AUTOSAR XML (schema 4-0-3)
package /ComponentTypes
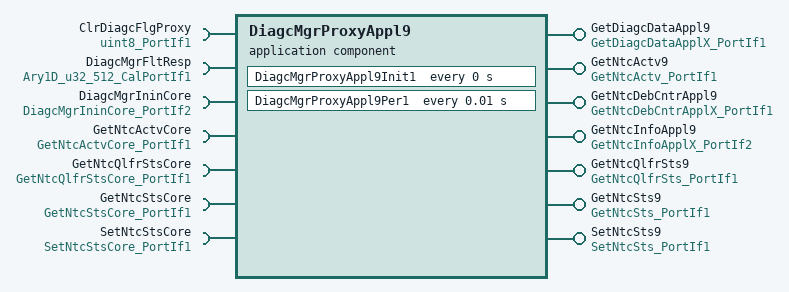
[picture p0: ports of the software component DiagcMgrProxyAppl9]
  application sw component type DiagcMgrProxyAppl9
    7 x provide port, all with server-com-spec{operation=Oper, queue-length=1}:
      GetDiagcDataAppl9: provided-interface=GetDiagcDataApplX_PortIf1
      GetNtcActv9: provided-interface=GetNtcActv_PortIf1
      GetNtcDebCntrAppl9: provided-interface=GetNtcDebCntrApplX_PortIf1
      GetNtcInfoAppl9: provided-interface=GetNtcInfoApplX_PortIf2
      GetNtcQlfrSts9: provided-interface=GetNtcQlfrSts_PortIf1
      GetNtcSts9: provided-interface=GetNtcSts_PortIf1
      SetNtcSts9: provided-interface=SetNtcSts_PortIf1
    7 x require port:
      ClrDiagcFlgProxy: nonqueued-receiver-com-spec{data-element=Val, filter=data-filter-type=ALWAYS, init-value=0}, required-interface=uint8_PortIf1
      DiagcMgrFltResp: parameter-require-com-spec{init-value=[0, 2147487488, 2147487488, 2147487488, 2147487488, 2147487488, 2147487488, 2147487488, 2147487488, 2147487488, 2147487488, 2147487488, 2147487488, 2147487488, 2147487488, 2147487488, 2147487488, 2147487488, 2147487488, 2147487488, 2147487488, 2147487488, 2147487488, 2147487488, 2147487488, 2147487488, 2147487488, 2147487488, 2147487488, 2147487488, 2147487488, 2147487488, 2147487488, 2147487488, 2147487488, 2147487488, 2147487488, 2147487488, 2147487488, 2147487488, 2147487488, 2147487488, 2147487488, 2147487488, 2147487488, 2147487488, 2147487488, 2147487488, 2147487488, 2147487488, 2147487488, 2147487488, 2147487488, 2147487488, 2147487488, 2147487488, 2147487488, 2147487488, 2147487488, 2147487488, 2147487488, 2147487488, 2147487488, 2147487488, 2147487488, 2147487488, 2147487488, 2147487488, 2147487488, 2147487488, 2147487488, 2147487488, 2147487488, 2147487488, 2147487488, 2147487488, 2147487488, 2147487488, 2147487488, 2147487488, 2147487488, 2147487488, 2147487488, 2147487488, 2147487488, 2147487488, 2147487488, 2147487488, 2147487488, 2147487488, 2147487488, 2147487488, 2147487488, 2147487488, 2147487488, 2147487488, 2147487488, 2147487488, 2147487488, 2147487488, 2147487488, 2147487488, 2147487488, 2147487488, 2147487488, 2147487488, 2147487488, 2147487488, 2147487488, 2147487488, 2147487488, 2147487488, 2147487488, 2147487488, 2147487488, 2147487488, 2147487488, 2147487488, 2147487488, 2147487488, 2147487488, 2147487488, 2147487488, 2147487488, 2147487488, 2147487488, 2147487488, 2147487488, 2147487488, 2147487488, 2147487488, 2147487488, 2147487488, 2147487488, 2147487488, 2147487488, 2147487488, 2147487488, 2147487488, 2147487488, 2147487488, 2147487488, 2147487488, 2147487488, 2147487488, 2147487488, 2147487488, 2147487488, 2147487488, 2147487488, 2147487488, 2147487488, 2147487488, 2147487488, 2147487488, 2147487488, 2147487488, 2147487488, 2147487488, 2147487488, 2147487488, 2147487488, 2147487488, 2147487488, 2147487488, 2147487488, 2147487488, 2147487488, 2147487488, 2147487488, 2147487488, 2147487488, 2147487488, 2147487488, 2147487488, 2147487488, 2147487488, 2147487488, 2147487488, 2147487488, 2147487488, 2147487488, 2147487488, 2147487488, 2147487488, 2147487488, 2147487488, 2147487488, 2147487488, 2147487488, 2147487488, 2147487488, 2147487488, 2147487488, 2147487488, 2147487488, 2147487488, 2147487488, 2147487488, 2147487488, 2147487488, 2147487488, 2147487488, 2147487488, 2147487488, 2147487488, 2147487488, 2147487488, 2147487488, 2147487488, 2147487488, 2147487488, 2147487488, 2147487488, 2147487488, 2147487488, 2147487488, 2147487488, 2147487488, 2147487488, 2147487488, 2147487488, 2147487488, 2147487488, 2147487488, 2147487488, 2147487488, 2147487488, 2147487488, 2147487488, 2147487488, 2147487488, 2147487488, 2147487488, 2147487488, 2147487488, 2147487488, 2147487488, 2147487488, 2147487488, 2147487488, 2147487488, 2147487488, 2147487488, 2147487488, 2147487488, 2147487488, 2147487488, 2147487488, 2147487488, 2147487488, 2147487488, 2147487488, 2147487488, 2147487488, 2147487488, 2147487488, 2147487488, 2147487488, 2147487488, 2147487488, 2147487488, 2147487488, 2147487488, 2147487488, 2147487488, 2147487488, 2147487488, 2147487488, 2147487488, 2147487488, 2147487488, 2147487488, 2147487488, 2147487488, 2147487488, 2147487488, 2147487488, 2147487488, 2147487488, 2147487488, 2147487488, 2147487488, 2147487488, 2147487488, 2147487488, 2147487488, 2147487488, 2147487488, 2147487488, 2147487488, 2147487488, 2147487488, 2147487488, 2147487488, 2147487488, 2147487488, 2147487488, 2147487488, 2147487488, 2147487488, 2147487488, 2147487488, 2147487488, 2147487488, 2147487488, 2147487488, 2147487488, 2147487488, 2147487488, 2147487488, 2147487488, 2147487488, 2147487488, 2147487488, 2147487488, 2147487488, 2147487488, 2147487488, 2147487488, 2147487488, 2147487488, 2147487488, 2147487488, 2147487488, 2147487488, 2147487488, 2147487488, 2147487488, 2147487488, 2147487488, 2147487488, 2147487488, 2147487488, 2147487488, 2147487488, 2147487488, 2147487488, 2147487488, 2147487488, 2147487488, 2147487488, 2147487488, 2147487488, 2147487488, 2147487488, 2147487488, 2147487488, 2147487488, 2147487488, 2147487488, 2147487488, 2147487488, 2147487488, 2147487488, 2147487488, 2147487488, 2147487488, 2147487488, 2147487488, 2147487488, 2147487488, 2147487488, 2147487488, 2147487488, 2147487488, 2147487488, 2147487488, 2147487488, 2147487488, 2147487488, 2147487488, 2147487488, 2147487488, 2147487488, 2147487488, 2147487488, 2147487488, 2147487488, 2147487488, 2147487488, 2147487488, 2147487488, 2147487488, 2147487488, 2147487488, 2147487488, 2147487488, 2147487488, 2147487488, 2147487488, 2147487488, 2147487488, 2147487488, 2147487488, 2147487488, 2147487488, 2147487488, 2147487488, 2147487488, 2147487488, 2147487488, 2147487488, 2147487488, 2147487488, 2147487488, 2147487488, 2147487488, 2147487488, 2147487488, 2147487488, 2147487488, 2147487488, 2147487488, 2147487488, 2147487488, 2147487488, 2147487488, 2147487488, 2147487488, 2147487488, 2147487488, 2147487488, 2147487488, 2147487488, 2147487488, 2147487488, 2147487488, 2147487488, 2147487488, 2147487488, 2147487488, 2147487488, 2147487488, 2147487488, 2147487488, 2147487488, 2147487488, 2147487488, 2147487488, 2147487488, 2147487488, 2147487488, 2147487488, 2147487488, 2147487488, 2147487488, 2147487488, 2147487488, 2147487488, 2147487488, 2147487488, 2147487488, 2147487488, 2147487488, 2147487488, 2147487488, 2147487488, 2147487488, 2147487488, 2147487488, 2147487488, 2147487488, 2147487488, 2147487488, 2147487488, 2147487488, 2147487488, 2147487488, 2147487488, 2147487488, 2147487488, 2147487488, 2147487488, 2147487488, 2147487488, 2147487488, 2147487488, 2147487488, 2147487488, 2147487488, 2147487488, 2147487488, 2147487488, 2147487488, 2147487488, 2147487488, 2147487488, 2147487488, 2147487488, 2147487488, 2147487488, 2147487488, 2147487488, 2147487488, 2147487488, 2147487488, 2147487488, 2147487488, 2147487488, 2147487488, 2147487488, 2147487488, 2147487488, 2147487488, 2147487488, 2147487488, 2147487488, 2147487488, 2147487488, 2147487488, 2147487488], parameter=Ary1D}, required-interface=Ary1D_u32_512_CalPortIf1
      DiagcMgrIninCore: required-interface=DiagcMgrIninCore_PortIf2
      GetNtcActvCore: required-interface=GetNtcActvCore_PortIf1
      GetNtcQlfrStsCore: required-interface=GetNtcQlfrStsCore_PortIf1
      GetNtcStsCore: required-interface=GetNtcStsCore_PortIf1
      SetNtcStsCore: required-interface=SetNtcStsCore_PortIf1
    behavior DiagcMgrProxyAppl9_InternalBehavior
      exclusive area DiagcMgrProxyAppl9
      ar-typed-per-instance-memorys:
        5 x data:
          DiagcData9: sw-calibration-access=READ-ONLY, type=DiagcDataRec1
          DiagcMgrNtcInfo9Ary: type=Ary1D_NtcInfoRec4_DiagcMgrProxyAppl9
          DiagcMgrNtcInfo9DebCntrAry: type=Ary1D_s16_DiagcMgrProxyAppl9
          PrevClrNtcFlg9: sw-calibration-access=READ-ONLY, type=uint8
          ProxySetNtcData9: sw-calibration-access=READ-ONLY, type=DiagcDataRec1
      timing event DiagcMgrProxyAppl9_InitEvent: start-on-event=DiagcMgrProxyAppl9Init1, period=0
      timing event TMT_DiagcMgrProxyAppl9Per1: start-on-event=DiagcMgrProxyAppl9Per1, period=0.01
      7 x operation invoked event:
        OIT_GetDiagcDataAppl9_Oper_GetDiagcDataAppl9_Oper: start-on-event=GetDiagcDataAppl9_Oper, operation=GetDiagcDataAppl9.Oper
        OIT_GetNtcActv9_Oper_GetNtcActv9_Oper: start-on-event=GetNtcActv9_Oper, operation=GetNtcActv9.Oper
        OIT_GetNtcDebCntrAppl9_Oper_GetNtcDebCntrAppl9_Oper: start-on-event=GetNtcDebCntrAppl9_Oper, operation=GetNtcDebCntrAppl9.Oper
        OIT_GetNtcInfoAppl9_Oper_GetNtcInfoAppl9_Oper: start-on-event=GetNtcInfoAppl9_Oper, operation=GetNtcInfoAppl9.Oper
        OIT_GetNtcQlfrSts9_Oper_GetNtcQlfrSts9_Oper: start-on-event=GetNtcQlfrSts9_Oper, operation=GetNtcQlfrSts9.Oper
        OIT_GetNtcSts9_Oper_GetNtcSts9_Oper: start-on-event=GetNtcSts9_Oper, operation=GetNtcSts9.Oper
        OIT_SetNtcSts9_Oper_SetNtcSts9_Oper: start-on-event=SetNtcSts9_Oper, operation=SetNtcSts9.Oper
      9 x runnable:
        DiagcMgrProxyAppl9Init1
          sync call SC_DiagcMgrIninCore_Oper: operation=DiagcMgrIninCore.Oper, timeout=0
        DiagcMgrProxyAppl9Per1: can-enter-exclusive-area=DiagcMgrProxyAppl9
          data-receive-point-by-arguments:
            access REC_ClrNtcFlg_Val: accessed-variable=ClrDiagcFlgProxy.Val
        GetDiagcDataAppl9_Oper
        GetNtcActv9_Oper: can-be-invoked-concurrently=true
          sync call SC_GetNtcActvCore_Oper: operation=GetNtcActvCore.Oper, timeout=0
        GetNtcDebCntrAppl9_Oper
        GetNtcInfoAppl9_Oper
        GetNtcQlfrSts9_Oper: can-be-invoked-concurrently=true
          sync call SC_GetNtcQlfrStsCore_Oper: operation=GetNtcQlfrStsCore.Oper, timeout=0
        GetNtcSts9_Oper: can-be-invoked-concurrently=true
          sync call SC_GetNtcStsCore_Oper: operation=GetNtcStsCore.Oper, timeout=0
        SetNtcSts9_Oper: can-be-invoked-concurrently=true
          sync call SC_SetNtcStsCore_Oper: operation=SetNtcStsCore.Oper, timeout=0
  swc implementation DiagcMgrProxyAppl9_Implementation: behavior=DiagcMgrProxyAppl9_InternalBehavior
    code-descriptors:
      code Default: artifact-descriptors=autosar-engineering-object={short-label=Default, category=SWSRC}
